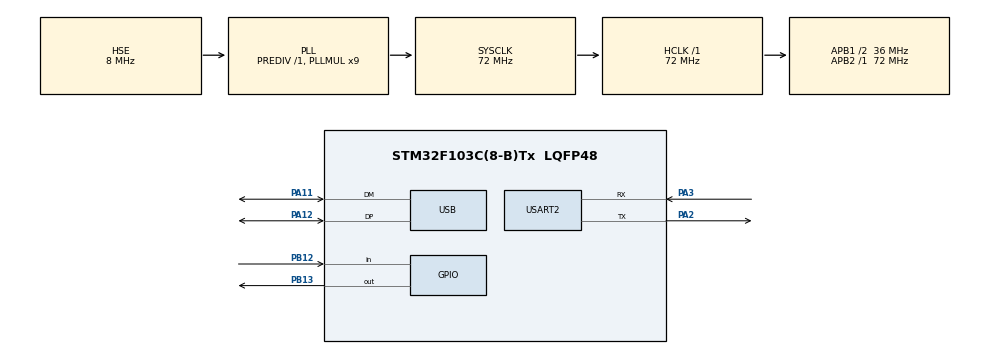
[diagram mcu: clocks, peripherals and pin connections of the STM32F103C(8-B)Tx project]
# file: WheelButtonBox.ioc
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Mcu.Family=STM32F1
Mcu.Name=STM32F103C(8-B)Tx
Mcu.Package=LQFP48
NVIC.PriorityGroup=NVIC_PRIORITYGROUP_4
NVIC.TIM3_IRQn=true\:0\:0\:false\:false\:true\:true\:true
NVIC.USB_LP_CAN1_RX0_IRQn=true\:0\:0\:false\:false\:true\:true\:true
PA11.Mode=Device
PA11.Signal=USB_DM
PA12.Mode=Device
PA12.Signal=USB_DP
PA13.Mode=Serial_Wire
PA13.Signal=SYS_JTMS-SWDIO
PA14.Mode=Serial_Wire
PA14.Signal=SYS_JTCK-SWCLK
PA2.Mode=Asynchronous
PA2.Signal=USART2_TX
PA3.Mode=Asynchronous
PA3.Signal=USART2_RX
PB12.GPIO_PuPd=GPIO_PULLUP
PB12.Signal=GPIO_Input
PB13.Signal=GPIO_Output
PD0-OSC_IN.Mode=HSE-External-Oscillator
PD0-OSC_IN.Signal=RCC_OSC_IN
PD1-OSC_OUT.Mode=HSE-External-Oscillator
PD1-OSC_OUT.Signal=RCC_OSC_OUT
ProjectManager.HeapSize=0x200
ProjectManager.StackSize=0x400
ProjectManager.TargetToolchain=Makefile
RCC.ADCPresc=RCC_ADCPCLK2_DIV6
RCC.AHBFreq_Value=72000000
RCC.APB1CLKDivider=RCC_HCLK_DIV2
RCC.APB1Freq_Value=36000000
RCC.APB1TimFreq_Value=72000000
RCC.APB2Freq_Value=72000000
RCC.APB2TimFreq_Value=72000000
RCC.HCLKFreq_Value=72000000
RCC.PLLMUL=RCC_PLL_MUL9
RCC.SYSCLKFreq_VALUE=72000000
RCC.SYSCLKSource=RCC_SYSCLKSOURCE_PLLCLK
RCC.USBFreq_Value=48000000
RCC.USBPrescaler=RCC_USBCLKSOURCE_PLL_DIV1_5
TIM3.Period=1000
TIM3.Prescaler=48
TIM3.TIM_MasterOutputTrigger=TIM_TRGO_UPDATE
USART2.VirtualMode=VM_ASYNC
USB.ep0_mps=DEP0CTL_MPS_64
USB_DEVICE.CLASS_NAME_FS=HID
USB_DEVICE.MANUFACTURER_STRING=Aleck
USB_DEVICE.PID_HID_FS=13
USB_DEVICE.PRODUCT_STRING_HID_FS=Sim wheel
USB_DEVICE.VID=0x0483
USB_DEVICE.VirtualMode=Hid
USB_DEVICE.VirtualModeFS=Hid_FS
VP_TIM3_VS_ClockSourceINT.Mode=Internal
VP_USB_DEVICE_VS_USB_DEVICE_HID_FS.Mode=HID_FS
board=hid_joystick_stm32

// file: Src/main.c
/* USER CODE BEGIN Header */
/**
  ******************************************************************************
  * @file           : main.c
  * @brief          : Main program body
  ******************************************************************************
  * @attention
  *
  * <h2><center>&copy; Copyright (c) 2020 STMicroelectronics.
  * All rights reserved.</center></h2>
  *
  * This software component is licensed by ST under Ultimate Liberty license
  * SLA0044, the "License"; You may not use this file except in compliance with
  * the License. You may obtain a copy of the License at:
  *                             www.st.com/SLA0044
  *
  ******************************************************************************
  */
/* USER CODE END Header */

#include "main.h"
#include "tim.h"
#include "usart.h"
#include "usb_device.h"
#include "gpio.h"

/* USER CODE BEGIN Includes */
#include "usbd_hid.h"
/* USER CODE END Includes */

void SystemClock_Config(void);

/* USER CODE BEGIN 0 */
extern USBD_HandleTypeDef hUsbDeviceFS;
uint8_t reportData[2] = {0, 0};
/* USER CODE END 0 */

int main(void)
{

  /* MCU Configuration--------------------------------------------------------*/

  /* Reset of all peripherals, Initializes the Flash interface and the Systick. */
  HAL_Init();

  /* Configure the system clock */
  SystemClock_Config();

  /* Initialize all configured peripherals */
  MX_GPIO_Init();
  MX_USB_DEVICE_Init();
  MX_TIM3_Init();
  MX_USART2_UART_Init();

  /* Infinite loop */
  while (1)
  {
    USBD_HID_SendReport(&hUsbDeviceFS, reportData, 2);
  }
}

void SystemClock_Config(void)
{
  RCC_OscInitTypeDef RCC_OscInitStruct = {0};
  RCC_ClkInitTypeDef RCC_ClkInitStruct = {0};
  RCC_PeriphCLKInitTypeDef PeriphClkInit = {0};

  /** Initializes the CPU, AHB and APB busses clocks
  */
  RCC_OscInitStruct.OscillatorType = RCC_OSCILLATORTYPE_HSE;
  RCC_OscInitStruct.HSEState = RCC_HSE_ON;
  RCC_OscInitStruct.HSEPredivValue = RCC_HSE_PREDIV_DIV1;
  RCC_OscInitStruct.HSIState = RCC_HSI_ON;
  RCC_OscInitStruct.PLL.PLLState = RCC_PLL_ON;
  RCC_OscInitStruct.PLL.PLLSource = RCC_PLLSOURCE_HSE;
  RCC_OscInitStruct.PLL.PLLMUL = RCC_PLL_MUL9;
  if (HAL_RCC_OscConfig(&RCC_OscInitStruct) != HAL_OK)
  {
    Error_Handler();
  }
  /** Initializes the CPU, AHB and APB busses clocks
  */
  RCC_ClkInitStruct.ClockType = RCC_CLOCKTYPE_HCLK|RCC_CLOCKTYPE_SYSCLK
                              |RCC_CLOCKTYPE_PCLK1|RCC_CLOCKTYPE_PCLK2;
  RCC_ClkInitStruct.SYSCLKSource = RCC_SYSCLKSOURCE_PLLCLK;
  RCC_ClkInitStruct.AHBCLKDivider = RCC_SYSCLK_DIV1;
  RCC_ClkInitStruct.APB1CLKDivider = RCC_HCLK_DIV2;
  RCC_ClkInitStruct.APB2CLKDivider = RCC_HCLK_DIV1;

  if (HAL_RCC_ClockConfig(&RCC_ClkInitStruct, FLASH_LATENCY_2) != HAL_OK)
  {
    Error_Handler();
  }
  PeriphClkInit.PeriphClockSelection = RCC_PERIPHCLK_USB;
  PeriphClkInit.UsbClockSelection = RCC_USBCLKSOURCE_PLL_DIV1_5;
  if (HAL_RCCEx_PeriphCLKConfig(&PeriphClkInit) != HAL_OK)
  {
    Error_Handler();
  }
}

void Error_Handler(void)
{
}

/************************ (C) COPYRIGHT STMicroelectronics *****END OF FILE****/
